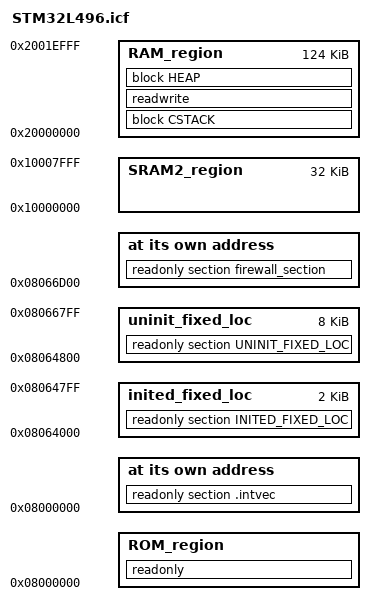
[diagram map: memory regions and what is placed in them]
/*###ICF### Section handled by ICF editor, don't touch! ****/
/*-Editor annotation file-*/
/* IcfEditorFile="$TOOLKIT_DIR$\config\ide\IcfEditor\cortex_v1_0.xml" */
/*-Specials-*/
define symbol __ICFEDIT_intvec_start__ = 0x08000000;
/*-Memory Regions-*/
define symbol __ICFEDIT_region_ROM_start__   = 0x08000000;
define symbol __ICFEDIT_region_ROM_end__     = 0x080fffff;
define symbol __ICFEDIT_region_RAM_start__   = 0x20000000;
define symbol __ICFEDIT_region_RAM_end__     = 0x2001EFFF;
define symbol __ICFEDIT_region_SRAM2_start__ = 0x10000000;
define symbol __ICFEDIT_region_SRAM2_end__   = 0x10007FFF;

/*-Sizes-*/
define symbol __ICFEDIT_size_cstack__ = 0x2000;
define symbol __ICFEDIT_size_heap__   = 0x10C00;
/**** End of ICF editor section. ###ICF###*/
define symbol heap_end=__ICFEDIT_region_RAM_end__;
export symbol heap_end;
define symbol heap2_end=__ICFEDIT_region_SRAM2_end__;
export symbol heap2_end;

define symbol heap_len=__ICFEDIT_size_heap__;
export symbol heap_len;
define symbol heap_start=heap_end - heap_len+1 ;
export symbol heap_start;

define symbol heap2_start=__ICFEDIT_region_SRAM2_start__;
export symbol heap2_start;
define symbol heap2_len=heap2_end-heap2_start+1;
export symbol heap2_len;

/*need to check project map to know this value*/
define symbol __bss_start__= 0x20000830;
export symbol __bss_start__;
define symbol __bss_end__=__ICFEDIT_region_RAM_end__;
export symbol __bss_end__;
define symbol _sdata=__ICFEDIT_region_RAM_start__;
export symbol _sdata;
define symbol _edata= __bss_start__ ;
export symbol _edata;
/* need more HEAP to run with mosquitto and RSA keys  0x7000 (exactly 0x6B6C )instead of 0x5800 with firewall ! */

define memory mem with size = 4G;

/* Definition of the static memory section for TLS certificates, keys, and wifi configuration data at the end of the first bank:
 *  Provision of 9K , 0x2400 bytes
 */
define symbol __ICFEDIT_region_FIXED_LOC_start__ = 0x08064000;
define region inited_fixed_loc = mem:[from __ICFEDIT_region_FIXED_LOC_start__ size 2K];
define region uninit_fixed_loc = mem:[from __ICFEDIT_region_FIXED_LOC_start__ + 2K size 8K];

define region ROM_region      = mem:[from __ICFEDIT_region_ROM_start__   to __ICFEDIT_region_ROM_end__] - uninit_fixed_loc;
define region RAM_region      = mem:[from __ICFEDIT_region_RAM_start__   to __ICFEDIT_region_RAM_end__];
define region SRAM2_region    = mem:[from __ICFEDIT_region_SRAM2_start__   to __ICFEDIT_region_SRAM2_end__];


define block CSTACK    with alignment = 8, size = __ICFEDIT_size_cstack__   { };
define block HEAP      with alignment = 8, size = __ICFEDIT_size_heap__     { };

initialize by copy { readwrite };
do not initialize  { section .noinit };

define exported symbol __firewall_ROM_start = 0x08066D00;
place at address mem:__firewall_ROM_start { readonly section firewall_section };


place at address mem:__ICFEDIT_intvec_start__ { readonly section .intvec };

place in ROM_region   { readonly };
place in RAM_region   { block CSTACK,
                        readwrite,
                        block HEAP };
						
						
place in uninit_fixed_loc  { readonly section UNINIT_FIXED_LOC };
place in inited_fixed_loc  { readonly section INITED_FIXED_LOC };
